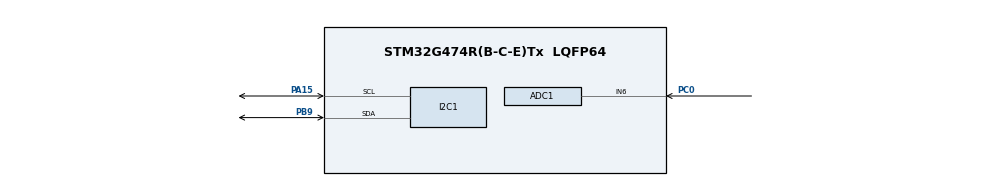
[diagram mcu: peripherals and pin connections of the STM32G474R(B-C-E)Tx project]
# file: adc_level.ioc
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ADC1.Channel-0\#ChannelRegularConversion=ADC_CHANNEL_6
ADC1.NbrOfConversionFlag=1
ADC1.OffsetNumber-0\#ChannelRegularConversion=ADC_OFFSET_NONE
ADC1.Rank-0\#ChannelRegularConversion=1
ADC1.Resolution=ADC_RESOLUTION_12B
ADC1.SamplingTime-0\#ChannelRegularConversion=ADC_SAMPLETIME_2CYCLES_5
ADC1.master=1
I2C1.Timing=0x40B285C2
Mcu.Family=STM32G4
Mcu.Name=STM32G474R(B-C-E)Tx
Mcu.Package=LQFP64
NVIC.PriorityGroup=NVIC_PRIORITYGROUP_4
PA13.Mode=Serial_Wire
PA13.Signal=SYS_JTMS-SWDIO
PA14.Mode=Serial_Wire
PA14.Signal=SYS_JTCK-SWCLK
PA15.Mode=I2C
PA15.Signal=I2C1_SCL
PB9.Mode=I2C
PB9.Signal=I2C1_SDA
PC0.Mode=IN6-Single-Ended
PC0.Signal=ADC1_IN6
ProjectManager.HeapSize=0x200
ProjectManager.StackSize=0x400
ProjectManager.TargetToolchain=STM32CubeIDE
RCC.ADC12Freq_Value=170000000
RCC.ADC345Freq_Value=170000000
RCC.AHBFreq_Value=170000000
RCC.APB1Freq_Value=170000000
RCC.APB1TimFreq_Value=170000000
RCC.APB2Freq_Value=170000000
RCC.APB2TimFreq_Value=170000000
RCC.CortexFreq_Value=170000000
RCC.EXTERNAL_CLOCK_VALUE=12288000
RCC.HCLKFreq_Value=170000000
RCC.HSE_VALUE=24000000
RCC.HSI48_VALUE=48000000
RCC.HSI_VALUE=16000000
RCC.LSE_VALUE=32768
RCC.PLLM=RCC_PLLM_DIV4
RCC.PLLN=85
RCC.RTCClockSelection=RCC_RTCCLKSOURCE_LSE
RCC.SYSCLKFreq_VALUE=170000000
RCC.SYSCLKSource=RCC_SYSCLKSOURCE_PLLCLK
RCC.USBFreq_Value=170000000
RCC.VCOOutputFreq_Value=340000000
VP_SYS_VS_DBSignals.Mode=DisableDeadBatterySignals
board=NUCLEO-G474RE

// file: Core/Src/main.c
/* USER CODE BEGIN Header */
/**
  ******************************************************************************
  * @file           : main.c
  * @brief          : Main program body
  ******************************************************************************
  * @attention
  *
  * Copyright (c) 2026 STMicroelectronics.
  * All rights reserved.
  *
  * This software is licensed under terms that can be found in the LICENSE file
  * in the root directory of this software component.
  * If no LICENSE file comes with this software, it is provided AS-IS.
  *
  ******************************************************************************
  */
/* USER CODE END Header */
#include "main.h"

/* USER CODE BEGIN PTD */
typedef enum
{
    REG_INPUT_0 = 0,
    REG_INPUT_1 = 1,
    REG_OUTPUT_0 = 2,
    REG_OUTPUT_1 = 3,
    REG_POLARITY_INV_0 = 4,
    REG_POLARITY_INV_1 = 5,
    REG_CONFIGURATION_0 = 6,
    REG_CONFIGURATION_1 = 7

} PCA9555_REGISTERS;
/* USER CODE END PTD */

/* USER CODE BEGIN PD */
#define PCA9555_ADDRESS   0x40

/* USER CODE END PD */

/* USER CODE BEGIN PV */
volatile uint16_t pot_raw = 0; // Ακατέργαστη τιμή 12-bit (0 - 4095)
volatile uint8_t  num_leds = 0; // Αριθμός αναμμένων LEDs (0 - 8)
/* USER CODE END PV */

void SystemClock_Config(void);
static void MX_GPIO_Init(void);
static void MX_ADC1_Init(void);
static void MX_I2C1_Init(void);
/* USER CODE BEGIN PFP */

void PCA9555_Write(uint8_t reg, uint8_t value);
uint8_t PCA9555_Read(uint8_t reg);
/* USER CODE END PFP */

int main(void)
{

  /* MCU Configuration--------------------------------------------------------*/

  /* Reset of all peripherals, Initializes the Flash interface and the Systick. */
  LL_APB2_GRP1_EnableClock(LL_APB2_GRP1_PERIPH_SYSCFG);
  LL_APB1_GRP1_EnableClock(LL_APB1_GRP1_PERIPH_PWR);

  /* System interrupt init*/
  NVIC_SetPriorityGrouping(NVIC_PRIORITYGROUP_4);

  /** Disable the internal Pull-Up in Dead Battery pins of UCPD peripheral
  */
  LL_PWR_DisableUCPDDeadBattery();

  /* Configure the system clock */
  SystemClock_Config();

  /* Initialize all configured peripherals */
  MX_GPIO_Init();
  MX_ADC1_Init();
  MX_I2C1_Init();
  /* USER CODE BEGIN 2 */
  /* 1. Ενεργοποίηση εσωτερικού σταθεροποιητή και Calibration ADC1 */
    LL_ADC_EnableInternalRegulator(ADC1);
    LL_mDelay(1);
    LL_ADC_StartCalibration(ADC1, LL_ADC_SINGLE_ENDED);
    while (LL_ADC_IsCalibrationOnGoing(ADC1));
    LL_ADC_Enable(ADC1);
    while (!LL_ADC_IsActiveFlag_ADRDY(ADC1));

    /* 2. Ρύθμιση του Port 0 του PCA9555 ως OUTPUT (0 = Output) */
    PCA9555_Write(REG_CONFIGURATION_0, 0x00);

    /* Αρχικό σβήσιμο όλων των Extended LEDs */
    PCA9555_Write(REG_OUTPUT_0, 0x00);
  /* USER CODE END 2 */

  /* Infinite loop */
  while (1)
    {

    /* USER CODE BEGIN 3 */
	    /* 1. Ανάγνωση 12-bit ADC από POT1 (PC0) */
	    LL_ADC_REG_StartConversion(ADC1);
	    while (!LL_ADC_IsActiveFlag_EOC(ADC1));
	    pot_raw = LL_ADC_REG_ReadConversionData12(ADC1);

	    /* 2. Υπολογισμός στάθμης (0 έως 8 LEDs) */
	    num_leds = (pot_raw + 64) / 512;
	    if (num_leds > 8) num_leds = 8;

	    /* 3. Δημιουργία δυαδικής μάσκας στάθμης */
	    uint8_t mask = 0;
	    if (num_leds > 0) {
	        mask = (1 << num_leds) - 1; // π.χ. num_leds=3 -> 0b00000111
	    }

	    /* 4. Εγγραφή της μάσκας απευθείας στο Extended Port 0 μέσω I2C */
	    PCA9555_Write(REG_OUTPUT_0, mask);

	    LL_mDelay(50); // Ρυθμός ανανέωσης 20 Hz
  /* USER CODE END 3 */
}

void SystemClock_Config(void)
{
  LL_FLASH_SetLatency(LL_FLASH_LATENCY_4);
  while(LL_FLASH_GetLatency() != LL_FLASH_LATENCY_4)
  {
  }
  LL_PWR_EnableRange1BoostMode();
  LL_RCC_HSI_Enable();
   /* Wait till HSI is ready */
  while(LL_RCC_HSI_IsReady() != 1)
  {
  }

  LL_RCC_HSI_SetCalibTrimming(64);
  LL_RCC_PLL_ConfigDomain_SYS(LL_RCC_PLLSOURCE_HSI, LL_RCC_PLLM_DIV_4, 85, LL_RCC_PLLR_DIV_2);
  LL_RCC_PLL_EnableDomain_SYS();
  LL_RCC_PLL_Enable();
   /* Wait till PLL is ready */
  while(LL_RCC_PLL_IsReady() != 1)
  {
  }

  LL_RCC_SetSysClkSource(LL_RCC_SYS_CLKSOURCE_PLL);
  LL_RCC_SetAHBPrescaler(LL_RCC_SYSCLK_DIV_2);
   /* Wait till System clock is ready */
  while(LL_RCC_GetSysClkSource() != LL_RCC_SYS_CLKSOURCE_STATUS_PLL)
  {
  }

  /* Insure 1us transition state at intermediate medium speed clock*/
  for (__IO uint32_t i = (170 >> 1); i !=0; i--);

  /* Set AHB prescaler*/
  LL_RCC_SetAHBPrescaler(LL_RCC_SYSCLK_DIV_1);
  LL_RCC_SetAPB1Prescaler(LL_RCC_APB1_DIV_1);
  LL_RCC_SetAPB2Prescaler(LL_RCC_APB2_DIV_1);

  LL_Init1msTick(170000000);

  LL_SetSystemCoreClock(170000000);
}

static void MX_ADC1_Init(void)
{

  LL_ADC_InitTypeDef ADC_InitStruct = {0};
  LL_ADC_REG_InitTypeDef ADC_REG_InitStruct = {0};
  LL_ADC_CommonInitTypeDef ADC_CommonInitStruct = {0};

  LL_GPIO_InitTypeDef GPIO_InitStruct = {0};

  LL_RCC_SetADCClockSource(LL_RCC_ADC12_CLKSOURCE_SYSCLK);

  /* Peripheral clock enable */
  LL_AHB2_GRP1_EnableClock(LL_AHB2_GRP1_PERIPH_ADC12);

  LL_AHB2_GRP1_EnableClock(LL_AHB2_GRP1_PERIPH_GPIOC);
  /**ADC1 GPIO Configuration
  PC0   ------> ADC1_IN6
  */
  GPIO_InitStruct.Pin = LL_GPIO_PIN_0;
  GPIO_InitStruct.Mode = LL_GPIO_MODE_ANALOG;
  GPIO_InitStruct.Pull = LL_GPIO_PULL_NO;
  LL_GPIO_Init(GPIOC, &GPIO_InitStruct);

  /** Common config
  */
  ADC_InitStruct.Resolution = LL_ADC_RESOLUTION_12B;
  ADC_InitStruct.DataAlignment = LL_ADC_DATA_ALIGN_RIGHT;
  ADC_InitStruct.LowPowerMode = LL_ADC_LP_MODE_NONE;
  LL_ADC_Init(ADC1, &ADC_InitStruct);
  ADC_REG_InitStruct.TriggerSource = LL_ADC_REG_TRIG_SOFTWARE;
  ADC_REG_InitStruct.SequencerLength = LL_ADC_REG_SEQ_SCAN_DISABLE;
  ADC_REG_InitStruct.SequencerDiscont = LL_ADC_REG_SEQ_DISCONT_DISABLE;
  ADC_REG_InitStruct.ContinuousMode = LL_ADC_REG_CONV_SINGLE;
  ADC_REG_InitStruct.DMATransfer = LL_ADC_REG_DMA_TRANSFER_NONE;
  ADC_REG_InitStruct.Overrun = LL_ADC_REG_OVR_DATA_PRESERVED;
  LL_ADC_REG_Init(ADC1, &ADC_REG_InitStruct);
  LL_ADC_SetGainCompensation(ADC1, 0);
  LL_ADC_SetOverSamplingScope(ADC1, LL_ADC_OVS_DISABLE);
  ADC_CommonInitStruct.CommonClock = LL_ADC_CLOCK_SYNC_PCLK_DIV4;
  ADC_CommonInitStruct.Multimode = LL_ADC_MULTI_INDEPENDENT;
  LL_ADC_CommonInit(__LL_ADC_COMMON_INSTANCE(ADC1), &ADC_CommonInitStruct);

  /* Disable ADC deep power down (enabled by default after reset state) */
  LL_ADC_DisableDeepPowerDown(ADC1);
  /* Enable ADC internal voltage regulator */
  LL_ADC_EnableInternalRegulator(ADC1);
  /* Delay for ADC internal voltage regulator stabilization. */
  /* Compute number of CPU cycles to wait for, from delay in us. */
  /* Note: Variable divided by 2 to compensate partially */
  /* CPU processing cycles (depends on compilation optimization). */
  /* Note: If system core clock frequency is below 200kHz, wait time */
  /* is only a few CPU processing cycles. */
  uint32_t wait_loop_index;
  wait_loop_index = ((LL_ADC_DELAY_INTERNAL_REGUL_STAB_US * (SystemCoreClock / (100000 * 2))) / 10);
  while(wait_loop_index != 0)
  {
    wait_loop_index--;
  }

  /** Configure Regular Channel
  */
  LL_ADC_REG_SetSequencerRanks(ADC1, LL_ADC_REG_RANK_1, LL_ADC_CHANNEL_6);
  LL_ADC_SetChannelSamplingTime(ADC1, LL_ADC_CHANNEL_6, LL_ADC_SAMPLINGTIME_2CYCLES_5);
  LL_ADC_SetChannelSingleDiff(ADC1, LL_ADC_CHANNEL_6, LL_ADC_SINGLE_ENDED);

}

static void MX_I2C1_Init(void)
{

  LL_I2C_InitTypeDef I2C_InitStruct = {0};

  LL_GPIO_InitTypeDef GPIO_InitStruct = {0};

  LL_RCC_SetI2CClockSource(LL_RCC_I2C1_CLKSOURCE_PCLK1);

  LL_AHB2_GRP1_EnableClock(LL_AHB2_GRP1_PERIPH_GPIOA);
  LL_AHB2_GRP1_EnableClock(LL_AHB2_GRP1_PERIPH_GPIOB);
  /**I2C1 GPIO Configuration
  PA15   ------> I2C1_SCL
  PB9   ------> I2C1_SDA
  */
  GPIO_InitStruct.Pin = LL_GPIO_PIN_15;
  GPIO_InitStruct.Mode = LL_GPIO_MODE_ALTERNATE;
  GPIO_InitStruct.Speed = LL_GPIO_SPEED_FREQ_LOW;
  GPIO_InitStruct.OutputType = LL_GPIO_OUTPUT_OPENDRAIN;
  GPIO_InitStruct.Pull = LL_GPIO_PULL_NO;
  GPIO_InitStruct.Alternate = LL_GPIO_AF_4;
  LL_GPIO_Init(GPIOA, &GPIO_InitStruct);

  GPIO_InitStruct.Pin = LL_GPIO_PIN_9;
  GPIO_InitStruct.Mode = LL_GPIO_MODE_ALTERNATE;
  GPIO_InitStruct.Speed = LL_GPIO_SPEED_FREQ_LOW;
  GPIO_InitStruct.OutputType = LL_GPIO_OUTPUT_OPENDRAIN;
  GPIO_InitStruct.Pull = LL_GPIO_PULL_NO;
  GPIO_InitStruct.Alternate = LL_GPIO_AF_4;
  LL_GPIO_Init(GPIOB, &GPIO_InitStruct);

  /* Peripheral clock enable */
  LL_APB1_GRP1_EnableClock(LL_APB1_GRP1_PERIPH_I2C1);

  /** I2C Initialization
  */
  I2C_InitStruct.PeripheralMode = LL_I2C_MODE_I2C;
  I2C_InitStruct.Timing = 0x40B285C2;
  I2C_InitStruct.AnalogFilter = LL_I2C_ANALOGFILTER_ENABLE;
  I2C_InitStruct.DigitalFilter = 0;
  I2C_InitStruct.OwnAddress1 = 0;
  I2C_InitStruct.TypeAcknowledge = LL_I2C_ACK;
  I2C_InitStruct.OwnAddrSize = LL_I2C_OWNADDRESS1_7BIT;
  LL_I2C_Init(I2C1, &I2C_InitStruct);
  LL_I2C_EnableAutoEndMode(I2C1);
  LL_I2C_SetOwnAddress2(I2C1, 0, LL_I2C_OWNADDRESS2_NOMASK);
  LL_I2C_DisableOwnAddress2(I2C1);
  LL_I2C_DisableGeneralCall(I2C1);
  LL_I2C_EnableClockStretching(I2C1);

}

static void MX_GPIO_Init(void)
{

  /* GPIO Ports Clock Enable */
  LL_AHB2_GRP1_EnableClock(LL_AHB2_GRP1_PERIPH_GPIOC);
  LL_AHB2_GRP1_EnableClock(LL_AHB2_GRP1_PERIPH_GPIOA);
  LL_AHB2_GRP1_EnableClock(LL_AHB2_GRP1_PERIPH_GPIOB);

}

/* USER CODE BEGIN 4 */
/*
 * Write one byte to PCA9555 register
 */
void PCA9555_Write(uint8_t reg, uint8_t value)
{
    LL_I2C_HandleTransfer(
        I2C1,
        PCA9555_ADDRESS,
        LL_I2C_ADDRSLAVE_7BIT,
        2,
        LL_I2C_MODE_AUTOEND,
        LL_I2C_GENERATE_START_WRITE
    );

    while (!LL_I2C_IsActiveFlag_TXIS(I2C1));

    LL_I2C_TransmitData8(I2C1, reg);

    while (!LL_I2C_IsActiveFlag_TXIS(I2C1));

    LL_I2C_TransmitData8(I2C1, value);

    while (!LL_I2C_IsActiveFlag_STOP(I2C1));

    LL_I2C_ClearFlag_STOP(I2C1);
}

/*
 * Read one byte from PCA9555 register
 */
uint8_t PCA9555_Read(uint8_t reg)
{
    uint8_t received_data = 0;

    /*
     * First phase:
     * Select register
     */
    LL_I2C_HandleTransfer(
        I2C1,
        PCA9555_ADDRESS,
        LL_I2C_ADDRSLAVE_7BIT,
        1,
        LL_I2C_MODE_SOFTEND,
        LL_I2C_GENERATE_START_WRITE
    );

    while (!LL_I2C_IsActiveFlag_TXIS(I2C1));

    LL_I2C_TransmitData8(I2C1, reg);

    while (!LL_I2C_IsActiveFlag_TC(I2C1));

    /*
     * Second phase:
     * Repeated START and read one byte
     */
    LL_I2C_HandleTransfer(
        I2C1,
        PCA9555_ADDRESS,
        LL_I2C_ADDRSLAVE_7BIT,
        1,
        LL_I2C_MODE_AUTOEND,
        LL_I2C_GENERATE_START_READ
    );

    while (!LL_I2C_IsActiveFlag_RXNE(I2C1));

    received_data = LL_I2C_ReceiveData8(I2C1);

    while (!LL_I2C_IsActiveFlag_STOP(I2C1));

    LL_I2C_ClearFlag_STOP(I2C1);

    return received_data;
}
/* USER CODE END 4 */

void Error_Handler(void)
{
  __disable_irq();
  while (1)
  {
  }
}
